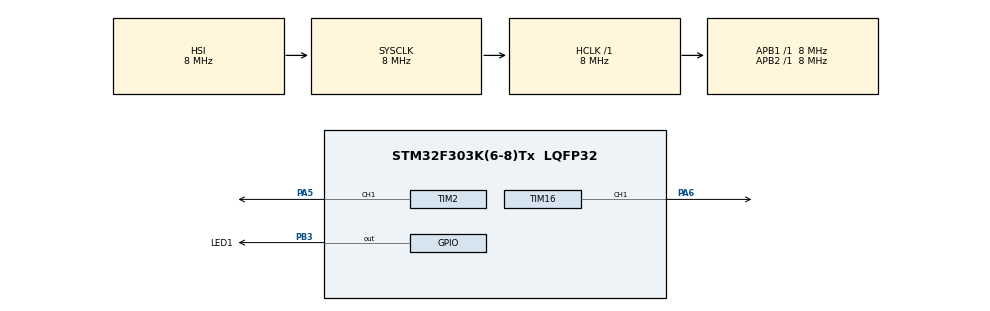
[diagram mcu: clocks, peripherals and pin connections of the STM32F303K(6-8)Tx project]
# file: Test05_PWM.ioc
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Mcu.Family=STM32F3
Mcu.Name=STM32F303K(6-8)Tx
Mcu.Package=LQFP32
NVIC.PriorityGroup=NVIC_PRIORITYGROUP_4
PA5.Signal=S_TIM2_CH1_ETR
PA6.Signal=S_TIM16_CH1
PB3.GPIO_Label=LED1
PB3.Signal=GPIO_Output
ProjectManager.HeapSize=0x200
ProjectManager.StackSize=0x400
ProjectManager.TargetToolchain=SW4STM32
RCC.AHBFreq_Value=8000000
RCC.APB1Freq_Value=8000000
RCC.APB2Freq_Value=8000000
RCC.CortexFreq_Value=8000000
RCC.HSE_VALUE=8000000
RCC.HSI_VALUE=8000000
RCC.SYSCLKFreq_VALUE=8000000
SH.S_TIM16_CH1.0=TIM16_CH1,PWM Generation1 CH1
SH.S_TIM2_CH1_ETR.0=TIM2_CH1,PWM Generation1 CH1
TIM16.Period=2000-1
TIM16.Prescaler=1080-1
TIM2.ClockDivision=TIM_CLOCKDIVISION_DIV1
TIM2.Period=2000-1
TIM2.Prescaler=1080-1
TIM2.Pulse-PWM\ Generation1\ CH1=0
VP_TIM16_VS_ClockSourceINT.Mode=Enable_Timer
board=Test05_PWM

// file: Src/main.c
/**
  ******************************************************************************
  * File Name          : main.c
  * Description        : Main program body
  ******************************************************************************
  *
  * COPYRIGHT(c) 2017 STMicroelectronics
  *
  * Redistribution and use in source and binary forms, with or without modification,
  * are permitted provided that the following conditions are met:
  *   1. Redistributions of source code must retain the above copyright notice,
  *      this list of conditions and the following disclaimer.
  *   2. Redistributions in binary form must reproduce the above copyright notice,
  *      this list of conditions and the following disclaimer in the documentation
  *      and/or other materials provided with the distribution.
  *   3. Neither the name of STMicroelectronics nor the names of its contributors
  *      may be used to endorse or promote products derived from this software
  *      without specific prior written permission.
  *
  * THIS SOFTWARE IS PROVIDED BY THE COPYRIGHT HOLDERS AND CONTRIBUTORS "AS IS"
  * AND ANY EXPRESS OR IMPLIED WARRANTIES, INCLUDING, BUT NOT LIMITED TO, THE
  * IMPLIED WARRANTIES OF MERCHANTABILITY AND FITNESS FOR A PARTICULAR PURPOSE ARE
  * DISCLAIMED. IN NO EVENT SHALL THE COPYRIGHT HOLDER OR CONTRIBUTORS BE LIABLE
  * FOR ANY DIRECT, INDIRECT, INCIDENTAL, SPECIAL, EXEMPLARY, OR CONSEQUENTIAL
  * DAMAGES (INCLUDING, BUT NOT LIMITED TO, PROCUREMENT OF SUBSTITUTE GOODS OR
  * SERVICES; LOSS OF USE, DATA, OR PROFITS; OR BUSINESS INTERRUPTION) HOWEVER
  * CAUSED AND ON ANY THEORY OF LIABILITY, WHETHER IN CONTRACT, STRICT LIABILITY,
  * OR TORT (INCLUDING NEGLIGENCE OR OTHERWISE) ARISING IN ANY WAY OUT OF THE USE
  * OF THIS SOFTWARE, EVEN IF ADVISED OF THE POSSIBILITY OF SUCH DAMAGE.
  *
  ******************************************************************************
  */
#include "main.h"
#include "stm32f3xx_hal.h"

TIM_HandleTypeDef htim2;
TIM_HandleTypeDef htim16;

/* USER CODE BEGIN PV */
/* Private variables ---------------------------------------------------------*/

/* USER CODE END PV */

void SystemClock_Config(void);
void Error_Handler(void);
static void MX_GPIO_Init(void);
static void MX_TIM2_Init(void);
static void MX_TIM16_Init(void);
void HAL_TIM_MspPostInit(TIM_HandleTypeDef *htim);

/* USER CODE BEGIN PFP */
/* Private function prototypes -----------------------------------------------*/

/* USER CODE END PFP */

/* USER CODE BEGIN 0 */
void user_tim2_1_setvalue(float value);//PA5
void user_tim16_1_setvalue(float value);//PA6
uint32_t uhPrescalerValue = 0;
#define  PERIOD_VALUE	500-1

/* USER CODE END 0 */

int main(void)
{

  /* USER CODE BEGIN 1 */
	float pwm_val=0.0;
  uhPrescalerValue = (uint32_t)(SystemCoreClock / 1000000) - 1;
  /* USER CODE END 1 */

  /* MCU Configuration----------------------------------------------------------*/

  /* Reset of all peripherals, Initializes the Flash interface and the Systick. */
  HAL_Init();

  /* Configure the system clock */
  SystemClock_Config();

  /* Initialize all configured peripherals */
  MX_GPIO_Init();
  MX_TIM2_Init();
  MX_TIM16_Init();

  /* Infinite loop */
  while (1)
  {

  /* USER CODE BEGIN 3 */
	HAL_Delay(10);
	pwm_val = pwm_val + 0.01;
	if(pwm_val > 1.0)pwm_val=0.0;
	user_tim2_1_setvalue(pwm_val);
	user_tim16_1_setvalue(pwm_val);
	HAL_GPIO_TogglePin(LED1_GPIO_Port,LED1_Pin);
	}
  /* USER CODE END 3 */

}

/** System Clock Configuration
*/
void SystemClock_Config(void)
{

  RCC_OscInitTypeDef RCC_OscInitStruct;
  RCC_ClkInitTypeDef RCC_ClkInitStruct;

    /**Initializes the CPU, AHB and APB busses clocks
    */
  RCC_OscInitStruct.OscillatorType = RCC_OSCILLATORTYPE_HSI;
  RCC_OscInitStruct.HSIState = RCC_HSI_ON;
  RCC_OscInitStruct.HSICalibrationValue = 16;
  RCC_OscInitStruct.PLL.PLLState = RCC_PLL_NONE;
  if (HAL_RCC_OscConfig(&RCC_OscInitStruct) != HAL_OK)
  {
    Error_Handler();
  }

    /**Initializes the CPU, AHB and APB busses clocks
    */
  RCC_ClkInitStruct.ClockType = RCC_CLOCKTYPE_HCLK|RCC_CLOCKTYPE_SYSCLK
                              |RCC_CLOCKTYPE_PCLK1|RCC_CLOCKTYPE_PCLK2;
  RCC_ClkInitStruct.SYSCLKSource = RCC_SYSCLKSOURCE_HSI;
  RCC_ClkInitStruct.AHBCLKDivider = RCC_SYSCLK_DIV1;
  RCC_ClkInitStruct.APB1CLKDivider = RCC_HCLK_DIV1;
  RCC_ClkInitStruct.APB2CLKDivider = RCC_HCLK_DIV1;

  if (HAL_RCC_ClockConfig(&RCC_ClkInitStruct, FLASH_LATENCY_0) != HAL_OK)
  {
    Error_Handler();
  }

    /**Configure the Systick interrupt time
    */
  HAL_SYSTICK_Config(HAL_RCC_GetHCLKFreq()/1000);

    /**Configure the Systick
    */
  HAL_SYSTICK_CLKSourceConfig(SYSTICK_CLKSOURCE_HCLK);

  /* SysTick_IRQn interrupt configuration */
  HAL_NVIC_SetPriority(SysTick_IRQn, 0, 0);
}

/* TIM2 init function */
static void MX_TIM2_Init(void)
{

  TIM_MasterConfigTypeDef sMasterConfig;
  TIM_OC_InitTypeDef sConfigOC;

  htim2.Instance = TIM2;
  htim2.Init.Prescaler = 1080-1;
  htim2.Init.CounterMode = TIM_COUNTERMODE_UP;
  htim2.Init.Period = 2000-1;
  htim2.Init.ClockDivision = TIM_CLOCKDIVISION_DIV1;
  if (HAL_TIM_PWM_Init(&htim2) != HAL_OK)
  {
    Error_Handler();
  }

  sMasterConfig.MasterOutputTrigger = TIM_TRGO_RESET;
  sMasterConfig.MasterSlaveMode = TIM_MASTERSLAVEMODE_DISABLE;
  if (HAL_TIMEx_MasterConfigSynchronization(&htim2, &sMasterConfig) != HAL_OK)
  {
    Error_Handler();
  }

  sConfigOC.OCMode = TIM_OCMODE_PWM1;
  sConfigOC.Pulse = 0;
  sConfigOC.OCPolarity = TIM_OCPOLARITY_HIGH;
  sConfigOC.OCFastMode = TIM_OCFAST_DISABLE;
  if (HAL_TIM_PWM_ConfigChannel(&htim2, &sConfigOC, TIM_CHANNEL_1) != HAL_OK)
  {
    Error_Handler();
  }

  HAL_TIM_MspPostInit(&htim2);

}

/* TIM16 init function */
static void MX_TIM16_Init(void)
{

  TIM_OC_InitTypeDef sConfigOC;
  TIM_BreakDeadTimeConfigTypeDef sBreakDeadTimeConfig;

  htim16.Instance = TIM16;
  htim16.Init.Prescaler = 1080-1;
  htim16.Init.CounterMode = TIM_COUNTERMODE_UP;
  htim16.Init.Period = 2000-1;
  htim16.Init.ClockDivision = TIM_CLOCKDIVISION_DIV1;
  htim16.Init.RepetitionCounter = 0;
  if (HAL_TIM_Base_Init(&htim16) != HAL_OK)
  {
    Error_Handler();
  }

  if (HAL_TIM_PWM_Init(&htim16) != HAL_OK)
  {
    Error_Handler();
  }

  sConfigOC.OCMode = TIM_OCMODE_PWM1;
  sConfigOC.Pulse = 0;
  sConfigOC.OCPolarity = TIM_OCPOLARITY_HIGH;
  sConfigOC.OCNPolarity = TIM_OCNPOLARITY_HIGH;
  sConfigOC.OCFastMode = TIM_OCFAST_DISABLE;
  sConfigOC.OCIdleState = TIM_OCIDLESTATE_RESET;
  sConfigOC.OCNIdleState = TIM_OCNIDLESTATE_RESET;
  if (HAL_TIM_PWM_ConfigChannel(&htim16, &sConfigOC, TIM_CHANNEL_1) != HAL_OK)
  {
    Error_Handler();
  }

  sBreakDeadTimeConfig.OffStateRunMode = TIM_OSSR_DISABLE;
  sBreakDeadTimeConfig.OffStateIDLEMode = TIM_OSSI_DISABLE;
  sBreakDeadTimeConfig.LockLevel = TIM_LOCKLEVEL_OFF;
  sBreakDeadTimeConfig.DeadTime = 0;
  sBreakDeadTimeConfig.BreakState = TIM_BREAK_DISABLE;
  sBreakDeadTimeConfig.BreakPolarity = TIM_BREAKPOLARITY_HIGH;
  sBreakDeadTimeConfig.BreakFilter = 0;
  sBreakDeadTimeConfig.AutomaticOutput = TIM_AUTOMATICOUTPUT_DISABLE;
  if (HAL_TIMEx_ConfigBreakDeadTime(&htim16, &sBreakDeadTimeConfig) != HAL_OK)
  {
    Error_Handler();
  }

  HAL_TIM_MspPostInit(&htim16);

}

/** Configure pins as
        * Analog
        * Input
        * Output
        * EVENT_OUT
        * EXTI
*/
static void MX_GPIO_Init(void)
{

  GPIO_InitTypeDef GPIO_InitStruct;

  /* GPIO Ports Clock Enable */
  __HAL_RCC_GPIOA_CLK_ENABLE();
  __HAL_RCC_GPIOB_CLK_ENABLE();

  /*Configure GPIO pin Output Level */
  HAL_GPIO_WritePin(LED1_GPIO_Port, LED1_Pin, GPIO_PIN_RESET);

  /*Configure GPIO pin : LED1_Pin */
  GPIO_InitStruct.Pin = LED1_Pin;
  GPIO_InitStruct.Mode = GPIO_MODE_OUTPUT_PP;
  GPIO_InitStruct.Pull = GPIO_NOPULL;
  GPIO_InitStruct.Speed = GPIO_SPEED_FREQ_LOW;
  HAL_GPIO_Init(LED1_GPIO_Port, &GPIO_InitStruct);

}

/* USER CODE BEGIN 4 */
void user_tim2_1_setvalue(float value)
{
    TIM_OC_InitTypeDef sConfigOC;

    sConfigOC.OCMode = TIM_OCMODE_PWM1;
    sConfigOC.Pulse = (uint32_t)((PERIOD_VALUE)*value);
    sConfigOC.OCPolarity = TIM_OCPOLARITY_HIGH;
    sConfigOC.OCFastMode = TIM_OCFAST_DISABLE;
    HAL_TIM_PWM_ConfigChannel(&htim2, &sConfigOC, TIM_CHANNEL_1);
    HAL_TIM_PWM_Start(&htim2, TIM_CHANNEL_1);
}
void user_tim16_1_setvalue(float value)
{
    TIM_OC_InitTypeDef sConfigOC;

    sConfigOC.OCMode = TIM_OCMODE_PWM1;
    sConfigOC.Pulse = (uint32_t)((PERIOD_VALUE)*value);
		sConfigOC.OCPolarity = TIM_OCPOLARITY_HIGH;
		sConfigOC.OCNPolarity = TIM_OCNPOLARITY_HIGH;
		sConfigOC.OCFastMode = TIM_OCFAST_DISABLE;
		sConfigOC.OCIdleState = TIM_OCIDLESTATE_RESET;
		sConfigOC.OCNIdleState = TIM_OCNIDLESTATE_RESET;
    HAL_TIM_PWM_ConfigChannel(&htim16, &sConfigOC, TIM_CHANNEL_1);
    HAL_TIM_PWM_Start(&htim16, TIM_CHANNEL_1);
}
/* USER CODE END 4 */

void Error_Handler(void)
{
  /* USER CODE BEGIN Error_Handler */
  /* User can add his own implementation to report the HAL error return state */
  while(1)
  {
		HAL_GPIO_WritePin(LED1_GPIO_Port,LED1_Pin,GPIO_PIN_SET);
		HAL_Delay(50);
		HAL_GPIO_WritePin(LED1_GPIO_Port,LED1_Pin,GPIO_PIN_RESET);
		HAL_Delay(50);
  }
  /* USER CODE END Error_Handler */
}

/************************ (C) COPYRIGHT STMicroelectronics *****END OF FILE****/
